# FOMU register map
Vendor: Foosn
Registers are 8-bit, read-write, reset 0x0 unless marked. A register's access mark holds for its fields unless they carry their own. Offsets are from the block's base; lines under a group give offsets from that group; [hi:lo] are bit positions; {n}, {i} and the like mark numbered series; 'fields as' and 'values as' point back to an identical list; <NAME> marks a mode.

## Memory map
0xE0000000 CTRL size 0x24
0xE0002800 TIMER0 size 0x44
0xE0004800 USB size 0x54
0xE0005800 TOUCH size 0xC
0xE0006000 REBOOT size 0x14
0xE0006800 RGB size 0x10
0xE0007000 VERSION size 0x3C
0xE0007800 LXSPI size 0xC
0xE0008000 MESSIBLE size 0xC

## Interrupts
2 timer0 (TIMER0)
3 usb (USB)

## CTRL
Base 0xE0000000
0x00 RESET
  [0] reset
0x04 SCRATCH3 reset 0x12 — Bits 24-31 of `CTRL_SCRATCH`.
  [7:0] scratch
0x08 SCRATCH2 reset 0x34 — Bits 16-23 of `CTRL_SCRATCH`.
  [7:0] scratch
0x0C SCRATCH1 reset 0x56 — Bits 8-15 of `CTRL_SCRATCH`.
  [7:0] scratch
0x10 SCRATCH0 reset 0x78 — Bits 0-7 of `CTRL_SCRATCH`.
  [7:0] scratch
0x14 BUS_ERRORS3 ro — Bits 24-31 of `CTRL_BUS_ERRORS`.
  [7:0] bus_errors
0x18 BUS_ERRORS2 ro — Bits 16-23 of `CTRL_BUS_ERRORS`.
  [7:0] bus_errors
0x1C BUS_ERRORS1 ro — Bits 8-15 of `CTRL_BUS_ERRORS`.
  [7:0] bus_errors
0x20 BUS_ERRORS0 ro — Bits 0-7 of `CTRL_BUS_ERRORS`.
  [7:0] bus_errors

## LXSPI
Base 0xE0007800
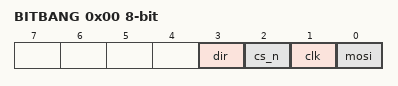
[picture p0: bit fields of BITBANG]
0x00 BITBANG — Bitbang controls for SPI output. Only standard 1x SPI is supported, meaning the IO2 and IO3 lines will be hardwired to `1` during bitbang mode.
  [3] dir — Dual/Quad SPI reuses pins SPI pin direction.
  [2] cs_n — Output value of SPI CSn line.
  [1] clk — Output value for SPI CLK line.
  [0] mosi — MOSI output pin, valid whenever `dir` is `0`.
0x04 MISO ro — Incoming value of MISO signal.
  [0] miso
0x08 BITBANG_EN — Write a `1` here to disable memory-mapped mode and enable bitbang mode.
  [0] bitbang_en

## MESSIBLE
Base 0xE0008000
0x00 IN — Write half of the FIFO to send data out the Messible. Writing to this register advances the write pointer automatically.
0x04 OUT ro — Read half of the FIFO to receive data on the Messible. Reading from this register advances the read pointer automatically.
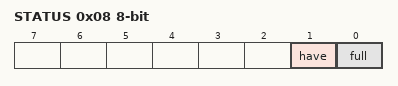
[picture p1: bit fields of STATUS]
0x08 STATUS ro
  [1] have — ``1`` if data can be read from the OUT FIFO.
  [0] full — ``0`` if more data can fit into the IN FIFO.

## REBOOT
Base 0xE0006000
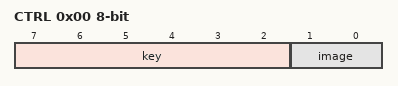
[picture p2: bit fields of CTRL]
0x00 CTRL — Provides support for rebooting the FPGA. You can select which of the four images to reboot to, just be sure to OR the image number with ``0xac``. For example, to reboot to the bootloader (image 0), write ``0xac``` to this register.
  [7:2] key — A reboot key used to prevent accidental reboots when writing to random areas of memory. To initiate a reboot, set this to ``0b101011``.
  [1:0] image — Which image to reboot to. ``SB_WARMBOOT`` supports four images that are configured at FPGA startup. The bootloader is image 0, so set these bits to 0 to reboot back into the bootloader.
0x04 ADDR3 — Bits 24-31 of `REBOOT_ADDR`. This sets the reset vector for the VexRiscv. This address will be used whenever the CPU is reset, for example through a debug bridge. You should update this address whenever you load a new program, to enable the debugger to run ``mon reset``
  [7:0] addr
0x08 ADDR2 — Bits 16-23 of `REBOOT_ADDR`.
  [7:0] addr
0x0C ADDR1 — Bits 8-15 of `REBOOT_ADDR`.
  [7:0] addr
0x10 ADDR0 — Bits 0-7 of `REBOOT_ADDR`.
  [7:0] addr

## RGB
Base 0xE0006800
0x00 DAT — This is the value for the ``SB_LEDDA_IP.DAT`` register. It is directly written into the ``SB_LEDDA_IP`` hardware block, so you should refer to http://www.latticesemi.com/view_document?document_id=50668. The contents of this register are written to the address specified in ``ADDR`` immediately upon writing this register.
0x04 ADDR — This register is directly connected to ``SB_LEDDA_IP.ADDR``. This register controls the address that is updated whenever ``DAT`` is written. Writing to this register has no immediate effect -- data isn't written until the ``DAT`` register is written.
  [3:0] addr
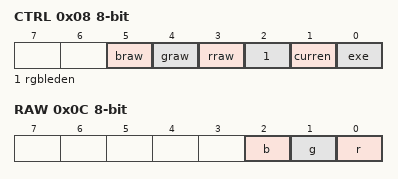
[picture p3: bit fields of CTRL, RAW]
0x08 CTRL — Control logic for the RGB LED and LEDDA hardware PWM LED block.
  [5] braw — Set this to ``1`` to enable raw control of the blue LED via the ``RAW.B`` register.
  [4] graw — Set this to ``1`` to enable raw control of the green LED via the ``RAW.G`` register.
  [3] rraw — Set this to ``1`` to enable raw control of the red LED via the ``RAW.R`` register.
  [2] rgbleden — Connected to ``SB_RGBA_DRV.RGBLEDEN``. Set this to ``1`` to enable the RGB PWM control logic.
  [1] curren — Connected to ``SB_RGBA_DRV.CURREN``. Set this to ``1`` to enable the current source.
  [0] exe — Connected to ``SB_LEDDA_IP.LEDDEXE``. Set this to ``1`` to enable the fading pattern.
0x0C RAW — Normally the hardware ``SB_LEDDA_IP`` block controls the brightness of the LED, creating a gentle fading pattern. However, by setting the appropriate bit in ``CTRL``, it is possible to manually control the three individual LEDs.
  [2] b — Raw value for the blue LED when ``CTRL.BRAW`` is ``1``.
  [1] g — Raw value for the green LED when ``CTRL.GRAW`` is ``1``.
  [0] r — Raw value for the red LED when ``CTRL.RRAW`` is ``1``.
